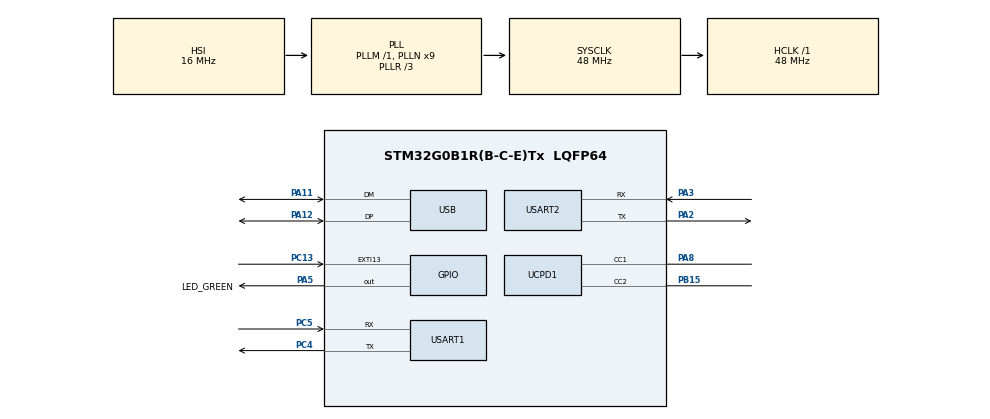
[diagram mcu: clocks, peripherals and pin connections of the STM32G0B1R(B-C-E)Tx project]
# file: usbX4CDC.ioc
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Dma.Request0=UCPD1_TX
Dma.Request1=UCPD1_RX
Dma.Request2=USART1_RX
Dma.Request3=USART1_TX
Dma.UCPD1_RX.1.Direction=DMA_PERIPH_TO_MEMORY
Dma.UCPD1_RX.1.EventEnable=DISABLE
Dma.UCPD1_RX.1.Instance=DMA1_Channel4
Dma.UCPD1_RX.1.MemDataAlignment=DMA_MDATAALIGN_BYTE
Dma.UCPD1_RX.1.MemInc=DMA_MINC_ENABLE
Dma.UCPD1_RX.1.Mode=DMA_NORMAL
Dma.UCPD1_RX.1.PeriphDataAlignment=DMA_PDATAALIGN_BYTE
Dma.UCPD1_RX.1.PeriphInc=DMA_PINC_DISABLE
Dma.UCPD1_RX.1.Polarity=HAL_DMAMUX_REQ_GEN_RISING
Dma.UCPD1_RX.1.Priority=DMA_PRIORITY_LOW
Dma.UCPD1_RX.1.RequestNumber=1
Dma.UCPD1_RX.1.SignalID=NONE
Dma.UCPD1_RX.1.SyncEnable=DISABLE
Dma.UCPD1_RX.1.SyncPolarity=HAL_DMAMUX_SYNC_NO_EVENT
Dma.UCPD1_RX.1.SyncRequestNumber=1
Dma.UCPD1_RX.1.SyncSignalID=NONE
Dma.UCPD1_TX.0.Direction=DMA_MEMORY_TO_PERIPH
Dma.UCPD1_TX.0.EventEnable=DISABLE
Dma.UCPD1_TX.0.Instance=DMA1_Channel2
Dma.UCPD1_TX.0.MemDataAlignment=DMA_MDATAALIGN_BYTE
Dma.UCPD1_TX.0.MemInc=DMA_MINC_ENABLE
Dma.UCPD1_TX.0.Mode=DMA_NORMAL
Dma.UCPD1_TX.0.PeriphDataAlignment=DMA_PDATAALIGN_BYTE
Dma.UCPD1_TX.0.PeriphInc=DMA_PINC_DISABLE
Dma.UCPD1_TX.0.Polarity=HAL_DMAMUX_REQ_GEN_RISING
Dma.UCPD1_TX.0.Priority=DMA_PRIORITY_LOW
Dma.UCPD1_TX.0.RequestNumber=1
Dma.UCPD1_TX.0.SignalID=NONE
Dma.UCPD1_TX.0.SyncEnable=DISABLE
Dma.UCPD1_TX.0.SyncPolarity=HAL_DMAMUX_SYNC_NO_EVENT
Dma.UCPD1_TX.0.SyncRequestNumber=1
Dma.UCPD1_TX.0.SyncSignalID=NONE
Dma.USART1_RX.2.Direction=DMA_PERIPH_TO_MEMORY
Dma.USART1_RX.2.EventEnable=DISABLE
Dma.USART1_RX.2.Instance=DMA1_Channel1
Dma.USART1_RX.2.MemDataAlignment=DMA_MDATAALIGN_BYTE
Dma.USART1_RX.2.MemInc=DMA_MINC_ENABLE
Dma.USART1_RX.2.Mode=DMA_NORMAL
Dma.USART1_RX.2.PeriphDataAlignment=DMA_PDATAALIGN_BYTE
Dma.USART1_RX.2.PeriphInc=DMA_PINC_DISABLE
Dma.USART1_RX.2.Polarity=HAL_DMAMUX_REQ_GEN_RISING
Dma.USART1_RX.2.Priority=DMA_PRIORITY_LOW
Dma.USART1_RX.2.RequestNumber=1
Dma.USART1_RX.2.SignalID=NONE
Dma.USART1_RX.2.SyncEnable=DISABLE
Dma.USART1_RX.2.SyncPolarity=HAL_DMAMUX_SYNC_NO_EVENT
Dma.USART1_RX.2.SyncRequestNumber=1
Dma.USART1_RX.2.SyncSignalID=NONE
Dma.USART1_TX.3.Direction=DMA_MEMORY_TO_PERIPH
Dma.USART1_TX.3.EventEnable=DISABLE
Dma.USART1_TX.3.Instance=DMA1_Channel3
Dma.USART1_TX.3.MemDataAlignment=DMA_MDATAALIGN_BYTE
Dma.USART1_TX.3.MemInc=DMA_MINC_ENABLE
Dma.USART1_TX.3.Mode=DMA_NORMAL
Dma.USART1_TX.3.PeriphDataAlignment=DMA_PDATAALIGN_BYTE
Dma.USART1_TX.3.PeriphInc=DMA_PINC_DISABLE
Dma.USART1_TX.3.Polarity=HAL_DMAMUX_REQ_GEN_RISING
Dma.USART1_TX.3.Priority=DMA_PRIORITY_LOW
Dma.USART1_TX.3.RequestNumber=1
Dma.USART1_TX.3.SignalID=NONE
Dma.USART1_TX.3.SyncEnable=DISABLE
Dma.USART1_TX.3.SyncPolarity=HAL_DMAMUX_SYNC_NO_EVENT
Dma.USART1_TX.3.SyncRequestNumber=1
Dma.USART1_TX.3.SyncSignalID=NONE
Mcu.Family=STM32G0
Mcu.Name=STM32G0B1R(B-C-E)Tx
Mcu.Package=LQFP64
NVIC.DMA1_Ch4_7_DMA2_Ch1_5_DMAMUX1_OVR_IRQn=true\:0\:0\:false\:false\:true\:false\:false\:true\:true
NVIC.DMA1_Channel1_IRQn=true\:0\:0\:false\:false\:true\:true\:false\:true\:true
NVIC.DMA1_Channel2_3_IRQn=true\:0\:0\:false\:false\:true\:true\:false\:true\:true
NVIC.EXTI4_15_IRQn=true\:0\:0\:false\:false\:true\:false\:true\:true\:true
NVIC.RCC_IRQn=true\:0\:0\:false\:false\:true\:false\:true\:false\:true
NVIC.TIM6_DAC_LPTIM1_IRQn=true\:3\:0\:false\:false\:true\:false\:false\:true\:true
NVIC.TimeBase=TIM6_DAC_LPTIM1_IRQn
NVIC.TimeBaseIP=TIM6
NVIC.USB_UCPD1_2_IRQn=true\:2\:0\:true\:false\:true\:false\:true\:true\:true
PA11\ [PA9].Mode=Device
PA11\ [PA9].Signal=USB_DM
PA12\ [PA10].Mode=Device
PA12\ [PA10].Signal=USB_DP
PA13.GPIO_Label=TMS
PA13.Mode=Serial_Wire
PA13.Signal=SYS_SWDIO
PA14-BOOT0.GPIO_Label=TCK
PA14-BOOT0.Mode=Serial_Wire
PA14-BOOT0.Signal=SYS_SWCLK
PA2.Mode=Asynchronous
PA2.Signal=USART2_TX
PA3.Mode=Asynchronous
PA3.Signal=USART2_RX
PA5.GPIO_Label=LED_GREEN
PA5.GPIO_Speed=GPIO_SPEED_FREQ_HIGH
PA5.Signal=GPIO_Output
PA8.Mode=Sink_AllSignals
PA8.Signal=UCPD1_CC1
PB15.Mode=Sink_AllSignals
PB15.Signal=UCPD1_CC2
PC13.Signal=GPXTI13
PC14-OSC32_IN\ (PC14).Mode=LSE-External-Oscillator
PC14-OSC32_IN\ (PC14).Signal=RCC_OSC32_IN
PC15-OSC32_OUT\ (PC15).Mode=LSE-External-Oscillator
PC15-OSC32_OUT\ (PC15).Signal=RCC_OSC32_OUT
PC4.Mode=Asynchronous
PC4.Signal=USART1_TX
PC5.Mode=Asynchronous
PC5.Signal=USART1_RX
PF0-OSC_IN\ (PF0).GPIO_Label=MCO
PF0-OSC_IN\ (PF0).Mode=HSE-External-Oscillator
PF0-OSC_IN\ (PF0).Signal=RCC_OSC_IN
PF1-OSC_OUT\ (PF1).Mode=HSE-External-Oscillator
PF1-OSC_OUT\ (PF1).Signal=RCC_OSC_OUT
ProjectManager.HeapSize=0x400
ProjectManager.StackSize=0x800
ProjectManager.TargetToolchain=STM32CubeIDE
RCC.ADCFreq_Value=48000000
RCC.AHBFreq_Value=48000000
RCC.CortexFreq_Value=48000000
RCC.EXTERNAL_CLOCK_VALUE=12288000
RCC.HCLKFreq_Value=48000000
RCC.HSE_VALUE=8000000
RCC.HSI48_VALUE=48000000
RCC.HSI_VALUE=16000000
RCC.PLLN=9
RCC.PLLR=RCC_PLLR_DIV3
RCC.SYSCLKFreq_VALUE=48000000
RCC.SYSCLKSource=RCC_SYSCLKSOURCE_PLLCLK
RCC.USBFreq_Value=48000000
RCC.VCOOutputFreq_Value=144000000
STMicroelectronics.X-CUBE-AZRTOS-G0.1.1.0.NetXDuoCcNetworkJjNetXDuoJjNXOoCore=true
STMicroelectronics.X-CUBE-AZRTOS-G0.1.1.0.TX_APP_MEM_POOL_SIZE=(24* 1024)
STMicroelectronics.X-CUBE-AZRTOS-G0.1.1.0.ThreadXCcRTOSJjThreadXJjCore=true
STMicroelectronics.X-CUBE-AZRTOS-G0.1.1.0.USBD_CDCACM_EPINCMD_ADDR=2
STMicroelectronics.X-CUBE-AZRTOS-G0.1.1.0.USBXCcUSBJjUSBXJjCoreSystem=true
STMicroelectronics.X-CUBE-AZRTOS-G0.1.1.0.USBXCcUSBJjUSBXJjUXOoDeviceOoClassOoCDCOoACM=true
STMicroelectronics.X-CUBE-AZRTOS-G0.1.1.0.USBXCcUSBJjUSBXJjUXOoDeviceOoControllers=true
STMicroelectronics.X-CUBE-AZRTOS-G0.1.1.0.USBXCcUSBJjUSBXJjUXOoDeviceOoCoreStack=true
STMicroelectronics.X-CUBE-AZRTOS-G0.1.1.0.USBXCcUSBJjUSBXJjUXOoNetworkOoDriver=true
STMicroelectronics.X-CUBE-AZRTOS-G0.1.1.0.UX_DEVICE_APP_MEM_POOL_SIZE=(72 * 1024)
STMicroelectronics.X-CUBE-AZRTOS-G0.1.1.0.UX_SLAVE_REQUEST_DATA_MAX_LENGTH=512
STMicroelectronics.X-CUBE-AZRTOS-G0.1.1.0.UX_THREAD_STACK_SIZE=(2048 * 8)
STMicroelectronics.X-CUBE-AZRTOS-G0.1.1.0_IsAnAzureRtosMw=true
USART1.VirtualMode-Asynchronous=VM_ASYNC
USART2.VirtualMode-Asynchronous=VM_ASYNC
USBPD.CAD_AccesorySupport_P0=USBPD_FALSE
VP_RCC_USB.Mode=CRS SYNC Source USB
VP_STMicroelectronics.X-CUBE-AZRTOS-G0_VS_NetworkJjNetXDuo_6.1.10_1.1.0.Mode=NetworkJjNetXDuo
VP_STMicroelectronics.X-CUBE-AZRTOS-G0_VS_RTOSJjThreadX_6.1.10_1.1.0.Mode=RTOSJjThreadX
VP_STMicroelectronics.X-CUBE-AZRTOS-G0_VS_USBJjUSBX_6.1.10_1.1.0.Mode=USBJjUSBX
VP_SYS_VS_tim6.Mode=TIM6
VP_USBPD_VS_PD3FULL.Mode=PD3_Full_Stack
VP_USBPD_VS_USBPD1.Mode=USBPD_P0
VP_USBPD_VS_usbpd_tim1.Mode=TIM1
VP_USBPD_VS_usbpd_usb_cohabitation.Mode=Enable USB Support
board=NUCLEO-G0B1RE

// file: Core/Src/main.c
/* USER CODE BEGIN Header */
/**
  ******************************************************************************
  * @file           : main.c
  * @brief          : Main program body
  ******************************************************************************
  * @attention
  *
  * Copyright (c) 2023 STMicroelectronics.
  * All rights reserved.
  *
  * This software is licensed under terms that can be found in the LICENSE file
  * in the root directory of this software component.
  * If no LICENSE file comes with this software, it is provided AS-IS.
  *
  ******************************************************************************
  */
/* USER CODE END Header */
#include "app_threadx.h"
#include "main.h"
#include "dma.h"
#include "ucpd.h"
#include "usart.h"
#include "usb_drd_fs.h"
#include "gpio.h"
#include "usbpd.h"

void SystemClock_Config(void);

int main(void)
{

  /* MCU Configuration--------------------------------------------------------*/

  /* Reset of all peripherals, Initializes the Flash interface and the Systick. */
  HAL_Init();

  /* Configure the system clock */
  SystemClock_Config();

  /* Initialize all configured peripherals */
  MX_GPIO_Init();
  MX_DMA_Init();
  MX_USB_DRD_FS_PCD_Init();
  MX_UCPD1_Init();
  MX_USART2_UART_Init();
  MX_USART1_UART_Init();
  /* Call PreOsInit function */
  USBPD_PreInitOs();

  MX_ThreadX_Init();

  /* We should never get here as control is now taken by the scheduler */
  /* Infinite loop */
  while (1)
  {

  }
}

void SystemClock_Config(void)
{
  RCC_OscInitTypeDef RCC_OscInitStruct = {0};
  RCC_ClkInitTypeDef RCC_ClkInitStruct = {0};
  RCC_CRSInitTypeDef pInit = {0};

  /** Configure the main internal regulator output voltage
  */
  HAL_PWREx_ControlVoltageScaling(PWR_REGULATOR_VOLTAGE_SCALE1);

  /** Initializes the RCC Oscillators according to the specified parameters
  * in the RCC_OscInitTypeDef structure.
  */
  RCC_OscInitStruct.OscillatorType = RCC_OSCILLATORTYPE_HSI|RCC_OSCILLATORTYPE_HSI48;
  RCC_OscInitStruct.HSIState = RCC_HSI_ON;
  RCC_OscInitStruct.HSI48State = RCC_HSI48_ON;
  RCC_OscInitStruct.HSIDiv = RCC_HSI_DIV1;
  RCC_OscInitStruct.HSICalibrationValue = RCC_HSICALIBRATION_DEFAULT;
  RCC_OscInitStruct.PLL.PLLState = RCC_PLL_ON;
  RCC_OscInitStruct.PLL.PLLSource = RCC_PLLSOURCE_HSI;
  RCC_OscInitStruct.PLL.PLLM = RCC_PLLM_DIV1;
  RCC_OscInitStruct.PLL.PLLN = 9;
  RCC_OscInitStruct.PLL.PLLP = RCC_PLLP_DIV2;
  RCC_OscInitStruct.PLL.PLLQ = RCC_PLLQ_DIV2;
  RCC_OscInitStruct.PLL.PLLR = RCC_PLLR_DIV3;
  if (HAL_RCC_OscConfig(&RCC_OscInitStruct) != HAL_OK)
  {
    Error_Handler();
  }

  /** Initializes the CPU, AHB and APB buses clocks
  */
  RCC_ClkInitStruct.ClockType = RCC_CLOCKTYPE_HCLK|RCC_CLOCKTYPE_SYSCLK
                              |RCC_CLOCKTYPE_PCLK1;
  RCC_ClkInitStruct.SYSCLKSource = RCC_SYSCLKSOURCE_PLLCLK;
  RCC_ClkInitStruct.AHBCLKDivider = RCC_SYSCLK_DIV1;
  RCC_ClkInitStruct.APB1CLKDivider = RCC_HCLK_DIV1;

  if (HAL_RCC_ClockConfig(&RCC_ClkInitStruct, FLASH_LATENCY_1) != HAL_OK)
  {
    Error_Handler();
  }

  /** Enable the SYSCFG APB clock
  */
  __HAL_RCC_CRS_CLK_ENABLE();

  /** Configures CRS
  */
  pInit.Prescaler = RCC_CRS_SYNC_DIV1;
  pInit.Source = RCC_CRS_SYNC_SOURCE_USB;
  pInit.Polarity = RCC_CRS_SYNC_POLARITY_RISING;
  pInit.ReloadValue = __HAL_RCC_CRS_RELOADVALUE_CALCULATE(48000000,1000);
  pInit.ErrorLimitValue = 34;
  pInit.HSI48CalibrationValue = 32;

  HAL_RCCEx_CRSConfig(&pInit);
}

void HAL_TIM_PeriodElapsedCallback(TIM_HandleTypeDef *htim)
{
  if (htim->Instance == TIM6) {
    HAL_IncTick();
  }
}

void Error_Handler(void)
{
  /* USER CODE BEGIN Error_Handler_Debug */
  /* User can add his own implementation to report the HAL error return state */
  __disable_irq();
  while (1)
  {
      HAL_GPIO_TogglePin(GPIOA, GPIO_PIN_5);
      tx_thread_sleep(10);
      HAL_GPIO_TogglePin(GPIOA, GPIO_PIN_5);
      tx_thread_sleep(90);
  }
  /* USER CODE END Error_Handler_Debug */
}
